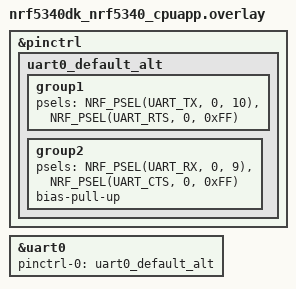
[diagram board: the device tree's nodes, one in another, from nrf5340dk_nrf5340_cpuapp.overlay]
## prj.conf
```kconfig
# nothing here

CONFIG_SRAM_SIZE=448
CONFIG_FLASH_SIZE=1024
CONFIG_SRAM_BASE_ADDRESS=0x20000000
CONFIG_NRF_CC3XX_PLATFORM=y
CONFIG_CONSOLE_INIT_PRIORITY=60
CONFIG_SOC_HFXO_CAP_INTERNAL=y
CONFIG_SOC_HFXO_CAP_INT_VALUE_X2=22

CONFIG_CLOCK_CONTROL_NRF_K32SRC_RC=y
CONFIG_SOC_ENABLE_LFXO=n
```

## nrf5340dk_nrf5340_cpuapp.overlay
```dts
// To get started, press Ctrl+Space to bring up the completion menu and view the available nodes.

// You can also use the buttons in the sidebar to perform actions on nodes.
// Actions currently available include:

// * Enabling / disabling the node
// * Adding the bus to a bus
// * Removing the node
// * Connecting ADC channels

// For more help, browse the DeviceTree documentation at https://docs.zephyrproject.org/latest/guides/dts/index.html
// You can also visit the nRF DeviceTree extension documentation at https://nrfconnect.github.io/vscode-nrf-connect/devicetree/nrfdevicetree.html


&pinctrl {
    uart0_default_alt: uart0_default_alt {
        group1 {
			psels = <NRF_PSEL(UART_TX, 0, 10)>,
				<NRF_PSEL(UART_RTS, 0, 0xFF)>;
		};
		group2 {
			psels = <NRF_PSEL(UART_RX, 0, 9)>,
				<NRF_PSEL(UART_CTS, 0, 0xFF)>;
			bias-pull-up;
		};
    };
};

&uart0 {
	pinctrl-0 = <&uart0_default_alt>;
};
```

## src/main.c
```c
/*
 * @Author: emmovo
 * @Date: 2022-11-11 14:27:18
 * @LastEditors: emmovo
 * @LastEditTime: 2022-11-11 16:34:16
 * @FilePath: \EM5340_test\hello_world\src\main.c
 * @Description: 
 * 
 * Copyright (c) 2022 by mingjkl@live.com/emmovo.com, All Rights Reserved. 
 */
/*
 * Copyright (c) 2012-2014 Wind River Systems, Inc.
 *
 * SPDX-License-Identifier: Apache-2.0
 */

#include <zephyr/zephyr.h>
#include "drivers/gpio.h"
#include "hal/nrf_gpio.h"

void main(void)
{
	nrf_gpio_cfg_output(NRF_GPIO_PIN_MAP(1,15));


	while(1)
	{
		nrf_gpio_pin_clear(NRF_GPIO_PIN_MAP(1,15));
		k_msleep(1000);
		printk("Hello World! %s\r\n", CONFIG_BOARD);
		nrf_gpio_pin_set(NRF_GPIO_PIN_MAP(1,15));
		k_msleep(1000);
	}
	
}
```
